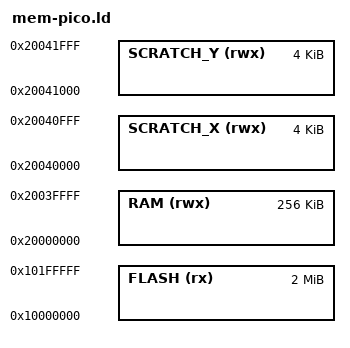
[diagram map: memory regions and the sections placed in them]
MEMORY
{
    FLASH(rx) : ORIGIN = 0x10000000, LENGTH = 2048k
    RAM(rwx) : ORIGIN =  0x20000000, LENGTH = 256k
    SCRATCH_X(rwx) : ORIGIN = 0x20040000, LENGTH = 4k
    SCRATCH_Y(rwx) : ORIGIN = 0x20041000, LENGTH = 4k
}
